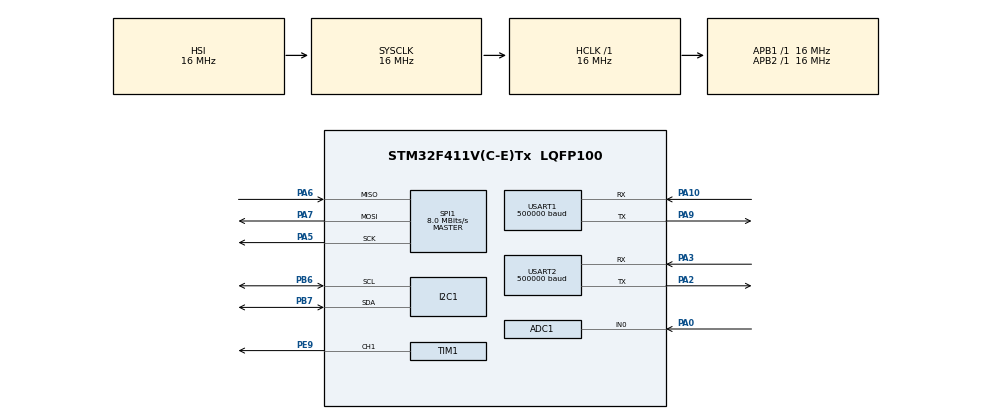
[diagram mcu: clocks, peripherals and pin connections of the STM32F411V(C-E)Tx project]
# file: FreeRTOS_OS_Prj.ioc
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ADC1.Channel-0\#ChannelRegularConversion=ADC_CHANNEL_0
ADC1.NbrOfConversionFlag=1
ADC1.Rank-0\#ChannelRegularConversion=1
ADC1.SamplingTime-0\#ChannelRegularConversion=ADC_SAMPLETIME_3CYCLES
ADC1.master=1
Mcu.Family=STM32F4
Mcu.Name=STM32F411V(C-E)Tx
Mcu.Package=LQFP100
NVIC.PriorityGroup=NVIC_PRIORITYGROUP_4
NVIC.TIM2_IRQn=true\:1\:0\:true\:false\:true\:false\:true\:true
NVIC.TimeBase=TIM2_IRQn
NVIC.TimeBaseIP=TIM2
NVIC.USART1_IRQn=true\:2\:0\:true\:false\:true\:true\:true\:true
NVIC.USART2_IRQn=true\:2\:0\:true\:false\:true\:true\:true\:true
PA0-WKUP.Signal=ADCx_IN0
PA10.Mode=Asynchronous
PA10.Signal=USART1_RX
PA2.Mode=Asynchronous
PA2.Signal=USART2_TX
PA3.Mode=Asynchronous
PA3.Signal=USART2_RX
PA5.Mode=Full_Duplex_Master
PA5.Signal=SPI1_SCK
PA6.Mode=Full_Duplex_Master
PA6.Signal=SPI1_MISO
PA7.Mode=Full_Duplex_Master
PA7.Signal=SPI1_MOSI
PA9.Mode=Asynchronous
PA9.Signal=USART1_TX
PB6.Mode=I2C
PB6.Signal=I2C1_SCL
PB7.Mode=I2C
PB7.Signal=I2C1_SDA
PE9.Signal=S_TIM1_CH1
ProjectManager.HeapSize=0x200
ProjectManager.StackSize=0x400
ProjectManager.TargetToolchain=STM32CubeIDE
RCC.AHBFreq_Value=16000000
RCC.APB1Freq_Value=16000000
RCC.APB2Freq_Value=16000000
RCC.CortexFreq_Value=16000000
RCC.HSE_VALUE=25000000
RCC.HSI_VALUE=16000000
RCC.LSE_VALUE=32768
RCC.SYSCLKFreq_VALUE=16000000
RCC.VCOOutputFreq_Value=192000000
SH.ADCx_IN0.0=ADC1_IN0,IN0
SH.S_TIM1_CH1.0=TIM1_CH1,PWM Generation1 CH1
SPI1.CalculateBaudRate=8.0 MBits/s
SPI1.Direction=SPI_DIRECTION_2LINES
SPI1.Mode=SPI_MODE_MASTER
SPI1.VirtualType=VM_MASTER
TIM1.Channel-PWM\ Generation1\ CH1=TIM_CHANNEL_1
USART1.BaudRate=500000
USART1.VirtualMode=VM_ASYNC
USART2.BaudRate=500000
USART2.VirtualMode=VM_ASYNC
VP_IWDG_VS_IWDG.Mode=IWDG_Activate
VP_SYS_VS_tim2.Mode=TIM2
board=custom

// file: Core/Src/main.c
/* USER CODE BEGIN Header */
/**
  ******************************************************************************
  * @file           : main.c
  * @brief          : Main program body
  ******************************************************************************
  * @attention
  *
  * Copyright (c) 2025 STMicroelectronics.
  * All rights reserved.
  *
  * This software is licensed under terms that can be found in the LICENSE file
  * in the root directory of this software component.
  * If no LICENSE file comes with this software, it is provided AS-IS.
  *
  ******************************************************************************
  */
/* USER CODE END Header */
#include "main.h"

/* USER CODE BEGIN Includes */
#include <init/init.h>
/* USER CODE END Includes */

ADC_HandleTypeDef hadc1;

I2C_HandleTypeDef hi2c1;

IWDG_HandleTypeDef hiwdg;

SPI_HandleTypeDef hspi1;

TIM_HandleTypeDef htim1;

UART_HandleTypeDef huart1;
UART_HandleTypeDef huart2;

void SystemClock_Config(void);
static void MX_GPIO_Init(void);
static void MX_ADC1_Init(void);
static void MX_I2C1_Init(void);
static void MX_SPI1_Init(void);
static void MX_TIM1_Init(void);
static void MX_USART1_UART_Init(void);
static void MX_IWDG_Init(void);
static void MX_USART2_UART_Init(void);

int main(void)
{

  /* MCU Configuration--------------------------------------------------------*/

  /* Reset of all peripherals, Initializes the Flash interface and the Systick. */
  HAL_Init();

  /* Configure the system clock */
  SystemClock_Config();

  /* Initialize all configured peripherals */
  MX_GPIO_Init();
  MX_ADC1_Init();
  MX_I2C1_Init();
  MX_SPI1_Init();
  MX_TIM1_Init();
  MX_USART1_UART_Init();
  MX_IWDG_Init();
  MX_USART2_UART_Init();
  /* USER CODE BEGIN 2 */
  os_add_drv_uart_handle		(&huart1,HW_ID_UART_1);
  os_add_drv_uart_handle		(&huart2,HW_ID_UART_2);
  os_add_drv_iic_handle			(&hi2c1,HW_ID_IIC_1);
  os_add_drv_spi_handle			(&hspi1,HW_ID_SPI_1);
  os_add_drv_adc_handle			(&hadc1,HW_ID_ADC_1);
  os_add_drv_timer_handle		(&htim1,HW_ID_TIM_1);
  os_add_drv_iwdg_handle		(&hiwdg);
  os_entry();

  /* USER CODE END 2 */

  /* Infinite loop */
  while (1)
  {

  }
}

void SystemClock_Config(void)
{
  RCC_OscInitTypeDef RCC_OscInitStruct = {0};
  RCC_ClkInitTypeDef RCC_ClkInitStruct = {0};

  /** Configure the main internal regulator output voltage
  */
  __HAL_RCC_PWR_CLK_ENABLE();
  __HAL_PWR_VOLTAGESCALING_CONFIG(PWR_REGULATOR_VOLTAGE_SCALE1);

  /** Initializes the RCC Oscillators according to the specified parameters
  * in the RCC_OscInitTypeDef structure.
  */
  RCC_OscInitStruct.OscillatorType = RCC_OSCILLATORTYPE_HSI|RCC_OSCILLATORTYPE_LSI;
  RCC_OscInitStruct.HSIState = RCC_HSI_ON;
  RCC_OscInitStruct.HSICalibrationValue = RCC_HSICALIBRATION_DEFAULT;
  RCC_OscInitStruct.LSIState = RCC_LSI_ON;
  RCC_OscInitStruct.PLL.PLLState = RCC_PLL_NONE;
  if (HAL_RCC_OscConfig(&RCC_OscInitStruct) != HAL_OK)
  {
    Error_Handler();
  }

  /** Initializes the CPU, AHB and APB buses clocks
  */
  RCC_ClkInitStruct.ClockType = RCC_CLOCKTYPE_HCLK|RCC_CLOCKTYPE_SYSCLK
                              |RCC_CLOCKTYPE_PCLK1|RCC_CLOCKTYPE_PCLK2;
  RCC_ClkInitStruct.SYSCLKSource = RCC_SYSCLKSOURCE_HSI;
  RCC_ClkInitStruct.AHBCLKDivider = RCC_SYSCLK_DIV1;
  RCC_ClkInitStruct.APB1CLKDivider = RCC_HCLK_DIV1;
  RCC_ClkInitStruct.APB2CLKDivider = RCC_HCLK_DIV1;

  if (HAL_RCC_ClockConfig(&RCC_ClkInitStruct, FLASH_LATENCY_0) != HAL_OK)
  {
    Error_Handler();
  }
}

static void MX_ADC1_Init(void)
{

  ADC_ChannelConfTypeDef sConfig = {0};

  /** Configure the global features of the ADC (Clock, Resolution, Data Alignment and number of conversion)
  */
  hadc1.Instance = ADC1;
  hadc1.Init.ClockPrescaler = ADC_CLOCK_SYNC_PCLK_DIV2;
  hadc1.Init.Resolution = ADC_RESOLUTION_12B;
  hadc1.Init.ScanConvMode = DISABLE;
  hadc1.Init.ContinuousConvMode = DISABLE;
  hadc1.Init.DiscontinuousConvMode = DISABLE;
  hadc1.Init.ExternalTrigConvEdge = ADC_EXTERNALTRIGCONVEDGE_NONE;
  hadc1.Init.ExternalTrigConv = ADC_SOFTWARE_START;
  hadc1.Init.DataAlign = ADC_DATAALIGN_RIGHT;
  hadc1.Init.NbrOfConversion = 1;
  hadc1.Init.DMAContinuousRequests = DISABLE;
  hadc1.Init.EOCSelection = ADC_EOC_SINGLE_CONV;
  if (HAL_ADC_Init(&hadc1) != HAL_OK)
  {
    Error_Handler();
  }

  /** Configure for the selected ADC regular channel its corresponding rank in the sequencer and its sample time.
  */
  sConfig.Channel = ADC_CHANNEL_0;
  sConfig.Rank = 1;
  sConfig.SamplingTime = ADC_SAMPLETIME_3CYCLES;
  if (HAL_ADC_ConfigChannel(&hadc1, &sConfig) != HAL_OK)
  {
    Error_Handler();
  }

}

static void MX_I2C1_Init(void)
{

  hi2c1.Instance = I2C1;
  hi2c1.Init.ClockSpeed = 100000;
  hi2c1.Init.DutyCycle = I2C_DUTYCYCLE_2;
  hi2c1.Init.OwnAddress1 = 0;
  hi2c1.Init.AddressingMode = I2C_ADDRESSINGMODE_7BIT;
  hi2c1.Init.DualAddressMode = I2C_DUALADDRESS_DISABLE;
  hi2c1.Init.OwnAddress2 = 0;
  hi2c1.Init.GeneralCallMode = I2C_GENERALCALL_DISABLE;
  hi2c1.Init.NoStretchMode = I2C_NOSTRETCH_DISABLE;
  if (HAL_I2C_Init(&hi2c1) != HAL_OK)
  {
    Error_Handler();
  }

}

static void MX_IWDG_Init(void)
{

  hiwdg.Instance = IWDG;
  hiwdg.Init.Prescaler = IWDG_PRESCALER_4;
  hiwdg.Init.Reload = 4095;
//  if (HAL_IWDG_Init(&hiwdg) != HAL_OK)
//  {
//    Error_Handler();
//  }

}

static void MX_SPI1_Init(void)
{

  /* SPI1 parameter configuration*/
  hspi1.Instance = SPI1;
  hspi1.Init.Mode = SPI_MODE_MASTER;
  hspi1.Init.Direction = SPI_DIRECTION_2LINES;
  hspi1.Init.DataSize = SPI_DATASIZE_8BIT;
  hspi1.Init.CLKPolarity = SPI_POLARITY_LOW;
  hspi1.Init.CLKPhase = SPI_PHASE_1EDGE;
  hspi1.Init.NSS = SPI_NSS_SOFT;
  hspi1.Init.BaudRatePrescaler = SPI_BAUDRATEPRESCALER_2;
  hspi1.Init.FirstBit = SPI_FIRSTBIT_MSB;
  hspi1.Init.TIMode = SPI_TIMODE_DISABLE;
  hspi1.Init.CRCCalculation = SPI_CRCCALCULATION_DISABLE;
  hspi1.Init.CRCPolynomial = 10;
  if (HAL_SPI_Init(&hspi1) != HAL_OK)
  {
    Error_Handler();
  }

}

static void MX_TIM1_Init(void)
{

  TIM_MasterConfigTypeDef sMasterConfig = {0};
  TIM_OC_InitTypeDef sConfigOC = {0};
  TIM_BreakDeadTimeConfigTypeDef sBreakDeadTimeConfig = {0};

  htim1.Instance = TIM1;
  htim1.Init.Prescaler = 0;
  htim1.Init.CounterMode = TIM_COUNTERMODE_UP;
  htim1.Init.Period = 65535;
  htim1.Init.ClockDivision = TIM_CLOCKDIVISION_DIV1;
  htim1.Init.RepetitionCounter = 0;
  htim1.Init.AutoReloadPreload = TIM_AUTORELOAD_PRELOAD_DISABLE;
  if (HAL_TIM_PWM_Init(&htim1) != HAL_OK)
  {
    Error_Handler();
  }
  sMasterConfig.MasterOutputTrigger = TIM_TRGO_RESET;
  sMasterConfig.MasterSlaveMode = TIM_MASTERSLAVEMODE_DISABLE;
  if (HAL_TIMEx_MasterConfigSynchronization(&htim1, &sMasterConfig) != HAL_OK)
  {
    Error_Handler();
  }
  sConfigOC.OCMode = TIM_OCMODE_PWM1;
  sConfigOC.Pulse = 0;
  sConfigOC.OCPolarity = TIM_OCPOLARITY_HIGH;
  sConfigOC.OCNPolarity = TIM_OCNPOLARITY_HIGH;
  sConfigOC.OCFastMode = TIM_OCFAST_DISABLE;
  sConfigOC.OCIdleState = TIM_OCIDLESTATE_RESET;
  sConfigOC.OCNIdleState = TIM_OCNIDLESTATE_RESET;
  if (HAL_TIM_PWM_ConfigChannel(&htim1, &sConfigOC, TIM_CHANNEL_1) != HAL_OK)
  {
    Error_Handler();
  }
  sBreakDeadTimeConfig.OffStateRunMode = TIM_OSSR_DISABLE;
  sBreakDeadTimeConfig.OffStateIDLEMode = TIM_OSSI_DISABLE;
  sBreakDeadTimeConfig.LockLevel = TIM_LOCKLEVEL_OFF;
  sBreakDeadTimeConfig.DeadTime = 0;
  sBreakDeadTimeConfig.BreakState = TIM_BREAK_DISABLE;
  sBreakDeadTimeConfig.BreakPolarity = TIM_BREAKPOLARITY_HIGH;
  sBreakDeadTimeConfig.AutomaticOutput = TIM_AUTOMATICOUTPUT_DISABLE;
  if (HAL_TIMEx_ConfigBreakDeadTime(&htim1, &sBreakDeadTimeConfig) != HAL_OK)
  {
    Error_Handler();
  }
  HAL_TIM_MspPostInit(&htim1);

}

static void MX_USART1_UART_Init(void)
{

  huart1.Instance = USART1;
  huart1.Init.BaudRate = 500000;
  huart1.Init.WordLength = UART_WORDLENGTH_8B;
  huart1.Init.StopBits = UART_STOPBITS_1;
  huart1.Init.Parity = UART_PARITY_NONE;
  huart1.Init.Mode = UART_MODE_TX_RX;
  huart1.Init.HwFlowCtl = UART_HWCONTROL_NONE;
  huart1.Init.OverSampling = UART_OVERSAMPLING_16;
  if (HAL_UART_Init(&huart1) != HAL_OK)
  {
    Error_Handler();
  }

}

static void MX_USART2_UART_Init(void)
{

  huart2.Instance = USART2;
  huart2.Init.BaudRate = 500000;
  huart2.Init.WordLength = UART_WORDLENGTH_8B;
  huart2.Init.StopBits = UART_STOPBITS_1;
  huart2.Init.Parity = UART_PARITY_NONE;
  huart2.Init.Mode = UART_MODE_TX_RX;
  huart2.Init.HwFlowCtl = UART_HWCONTROL_NONE;
  huart2.Init.OverSampling = UART_OVERSAMPLING_16;
  if (HAL_UART_Init(&huart2) != HAL_OK)
  {
    Error_Handler();
  }

}

static void MX_GPIO_Init(void)
{

  /* GPIO Ports Clock Enable */
  __HAL_RCC_GPIOA_CLK_ENABLE();
  __HAL_RCC_GPIOE_CLK_ENABLE();
  __HAL_RCC_GPIOB_CLK_ENABLE();

}

void HAL_TIM_PeriodElapsedCallback(TIM_HandleTypeDef *htim)
{
  if (htim->Instance == TIM2)
  {
    HAL_IncTick();
  }
}

void Error_Handler(void)
{
  __disable_irq();
  while (1)
  {
  }
}
